# iostr731 register map
Registers from a debugger description file.
Registers are 16-bit, access not given, no defined reset value unless marked. A register's access mark holds for its fields unless they carry their own. Addresses are absolute; registers are grouped by the start of their names; lines under a group give offsets from that group; [hi:lo] are bit positions; {n}, {i} and the like mark numbered series; 'fields as' and 'values as' point back to an identical list; <NAME> marks a mode.

## ARB
0x20000000 ARB_TOR 32-bit
  [15:0] TIMEOUT
0x20000004 ARB_PRIOR 32-bit
  [1:0] PRIORITY
0x2000000C ARB_CTRL 32-bit
  [1] ABORT

## CFG
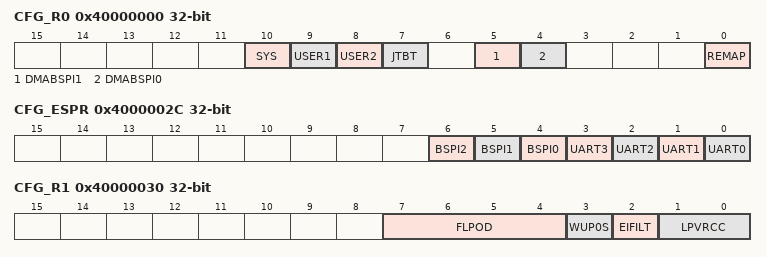
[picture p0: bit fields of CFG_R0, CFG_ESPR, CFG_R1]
0x40000000 CFG_R0 32-bit
  [10] SYS, [9] USER1, [8] USER2, [7] JTBT, [5] DMABSPI1, [4] DMABSPI0, [0] REMAP
0x40000004 CFG_EITE0 32-bit
  [15:0] EITE0
0x40000008 CFG_PCGR0 32-bit
0x4000000C CFG_PCGR1 32-bit
0x40000010 CFG_PECGR0 32-bit
0x40000014 CFG_PECGR1 32-bit
0x40000018 CFG_PCGRB0 32-bit
0x4000001C CFG_PCGRB1 32-bit
0x40000020 CFG_TIMSR 32-bit
  [9:0] TIMECKS
0x40000024 CFG_EITE1 32-bit
  [15:0] EITE1
0x40000028 CFG_EITE2 32-bit
  [15:0] EITE2
0x4000002C CFG_ESPR 32-bit
  [6] BSPI2, [5] BSPI1, [4] BSPI0, [n] UART{n} (n=0..3)
0x40000030 CFG_R1 32-bit
  [7:4] FLPOD, [3] WUP0S, [2] EIFILT, [1:0] LPVRCC
0x40000034 CFG_DIDR 32-bit

## PRCCU
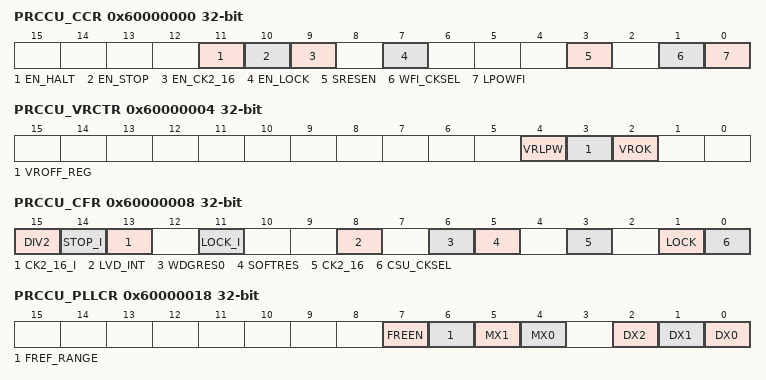
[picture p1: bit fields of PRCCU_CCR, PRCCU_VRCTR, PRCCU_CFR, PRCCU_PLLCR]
0x60000000 PRCCU_CCR 32-bit
  [11] EN_HALT, [10] EN_STOP, [9] EN_CK2_16, [7] EN_LOCK, [3] SRESEN, [1] WFI_CKSEL, [0] LPOWFI
0x60000004 PRCCU_VRCTR 32-bit
  [4] VRLPW, [3] VROFF_REG, [2] VROK
0x60000008 PRCCU_CFR 32-bit
  [15] DIV2, [14] STOP_I, [13] CK2_16_I, [11] LOCK_I, [8] LVD_INT, [6] WDGRES0, [5] SOFTRES, [3] CK2_16, [1] LOCK, [0] CSU_CKSEL
0x60000018 PRCCU_PLLCR 32-bit
  [7] FREEN, [6] FREF_RANGE, [5] MX1, [4] MX0, [2] DX2, [1] DX1, [0] DX0
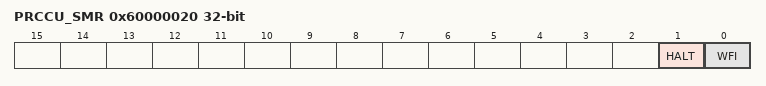
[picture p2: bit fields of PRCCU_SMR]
0x60000020 PRCCU_SMR 32-bit
  [1] HALT, [0] WFI
0x60000028 PRCCU_RTCPR 32-bit
  [3:0] RTCP

## FLASH
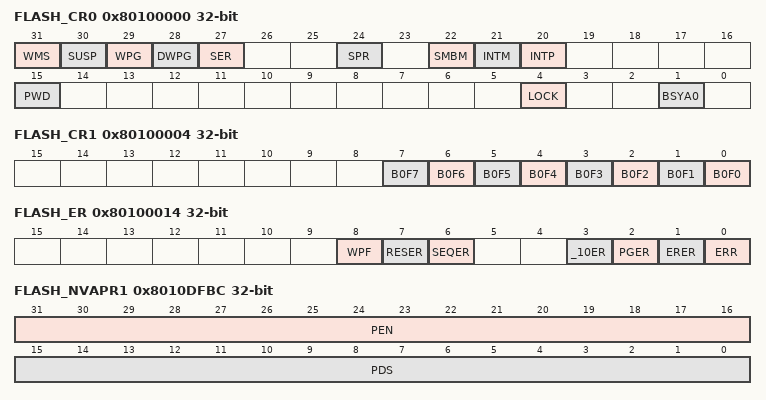
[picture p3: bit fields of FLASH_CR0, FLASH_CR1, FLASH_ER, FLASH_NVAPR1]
0x80100000 FLASH_CR0 32-bit
  [31] WMS, [30] SUSP, [29] WPG, [28] DWPG, [27] SER, [24] SPR, [22] SMBM, [21] INTM, [20] INTP, [15] PWD, [4] LOCK, [1] BSYA0
0x80100004 FLASH_CR1 32-bit
  [n] B0F{n} (n=0..7)
0x80100008 FLASH_DR0 32-bit
0x8010000C FLASH_DR1 32-bit
0x80100010 FLASH_AR 32-bit
  [20:0] ADD
0x80100014 FLASH_ER 32-bit
  [8] WPF, [7] RESER, [6] SEQER, [3] _10ER, [2] PGER, [1] ERER, [0] ERR
0x8010DFB0 FLASH_NVWPAR 32-bit
  [7:0] W0P
0x8010DFB8 FLASH_NVAPR0 32-bit
  [1] DBGP
0x8010DFBC FLASH_NVAPR1 32-bit
  [31:16] PEN, [15:0] PDS

## APB0
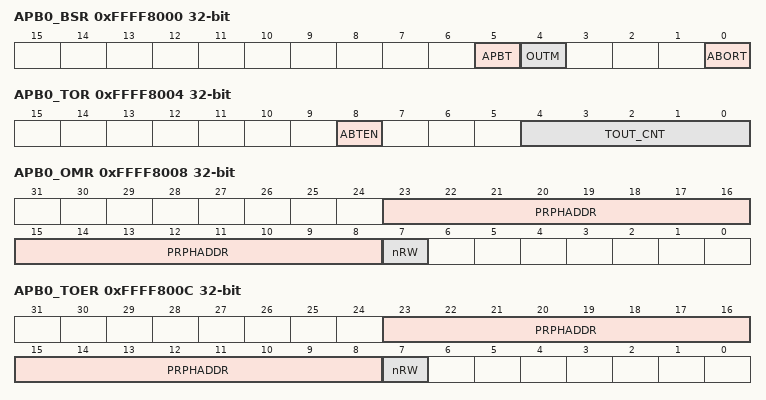
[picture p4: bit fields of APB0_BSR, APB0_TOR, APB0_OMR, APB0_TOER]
0xFFFF8000 APB0_BSR 32-bit
  [5] APBT, [4] OUTM, [0] ABORT
0xFFFF8004 APB0_TOR 32-bit
  [8] ABTEN, [4:0] TOUT_CNT
0xFFFF8008 APB0_OMR 32-bit
  [23:8] PRPHADDR, [7] nRW
0xFFFF800C APB0_TOER 32-bit
  [23:8] PRPHADDR, [7] nRW

## I2C0
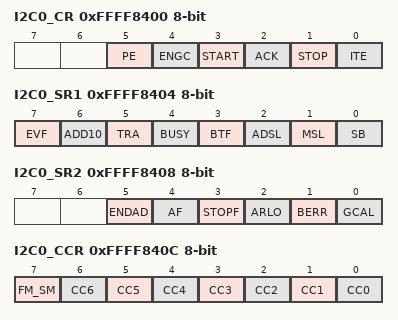
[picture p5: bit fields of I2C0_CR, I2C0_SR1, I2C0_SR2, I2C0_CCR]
0xFFFF8400 I2C0_CR 8-bit
  [5] PE, [4] ENGC, [3] START, [2] ACK, [1] STOP, [0] ITE
0xFFFF8404 I2C0_SR1 8-bit
  [7] EVF, [6] ADD10, [5] TRA, [4] BUSY, [3] BTF, [2] ADSL, [1] MSL, [0] SB
0xFFFF8408 I2C0_SR2 8-bit
  [5] ENDAD, [4] AF, [3] STOPF, [2] ARLO, [1] BERR, [0] GCAL
0xFFFF840C I2C0_CCR 8-bit
  [7] FM_SM, [n] CC{n} (n=0..6)
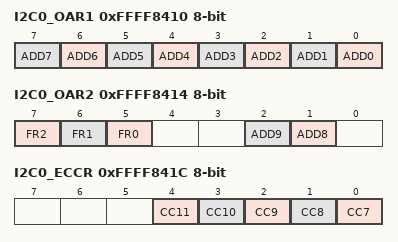
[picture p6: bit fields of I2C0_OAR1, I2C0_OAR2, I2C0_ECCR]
0xFFFF8410 I2C0_OAR1 8-bit
  [n] ADD{n} (n=0..7)
0xFFFF8414 I2C0_OAR2 8-bit
  [7] FR2, [6] FR1, [5] FR0, [2] ADD9, [1] ADD8
0xFFFF8418 I2C0_DR 8-bit
0xFFFF841C I2C0_ECCR 8-bit
  [n-7] CC{n} (n=7..11)
